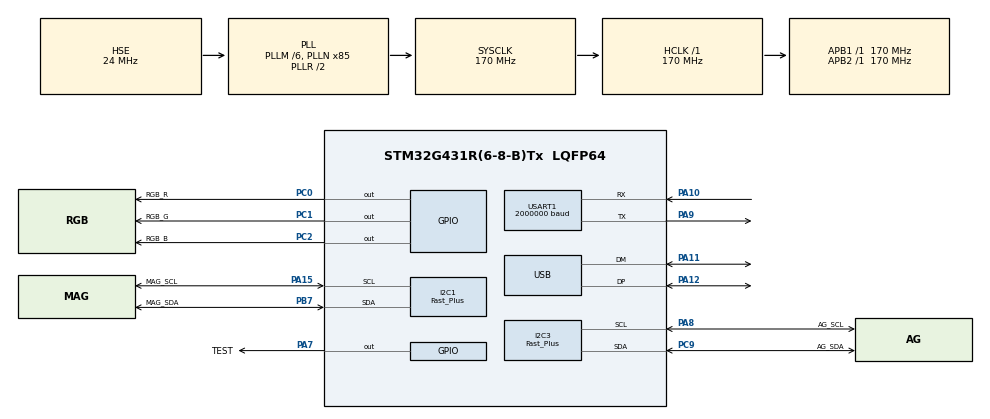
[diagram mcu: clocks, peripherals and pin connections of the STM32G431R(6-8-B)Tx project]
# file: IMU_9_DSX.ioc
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I2C1.CustomTiming=Disabled
I2C1.I2C_Fall_Time=0
I2C1.I2C_Rise_Time=0
I2C1.I2C_Speed_Mode=I2C_Fast_Plus
I2C1.Timing=0x00802172
I2C3.Analog_Filter=I2C_ANALOGFILTER_DISABLE
I2C3.CustomTiming=Disabled
I2C3.I2C_Speed_Mode=I2C_Fast_Plus
I2C3.Timing=0x00802C78
Mcu.Family=STM32G4
Mcu.Name=STM32G431R(6-8-B)Tx
Mcu.Package=LQFP64
NVIC.PriorityGroup=NVIC_PRIORITYGROUP_4
NVIC.TIM2_IRQn=true\:0\:0\:false\:false\:true\:true\:true\:true
NVIC.USART1_IRQn=true\:1\:0\:true\:false\:true\:true\:true\:true
NVIC.USB_LP_IRQn=true\:0\:0\:false\:false\:true\:false\:true\:true
PA10.Mode=Asynchronous
PA10.Signal=USART1_RX
PA11.Mode=Device
PA11.Signal=USB_DM
PA12.Mode=Device
PA12.Signal=USB_DP
PA13.Mode=Serial_Wire
PA13.Signal=SYS_JTMS-SWDIO
PA14.Mode=Serial_Wire
PA14.Signal=SYS_JTCK-SWCLK
PA15.GPIO_Label=MAG_SCL
PA15.Mode=I2C
PA15.Signal=I2C1_SCL
PA7.GPIO_Label=TEST
PA7.Signal=GPIO_Output
PA8.GPIO_Label=AG_SCL
PA8.Mode=I2C
PA8.Signal=I2C3_SCL
PA9.Mode=Asynchronous
PA9.Signal=USART1_TX
PB7.GPIO_Label=MAG_SDA
PB7.Mode=I2C
PB7.Signal=I2C1_SDA
PC0.GPIO_Label=RGB_R
PC0.Signal=GPIO_Output
PC1.GPIO_Label=RGB_G
PC1.Signal=GPIO_Output
PC2.GPIO_Label=RGB_B
PC2.Signal=GPIO_Output
PC9.GPIO_Label=AG_SDA
PC9.Mode=I2C
PC9.Signal=I2C3_SDA
PF0-OSC_IN.Mode=HSE-External-Oscillator
PF0-OSC_IN.Signal=RCC_OSC_IN
PF1-OSC_OUT.Mode=HSE-External-Oscillator
PF1-OSC_OUT.Signal=RCC_OSC_OUT
ProjectManager.HeapSize=0x400
ProjectManager.StackSize=0x800
ProjectManager.TargetToolchain=STM32CubeIDE
RCC.ADC12Freq_Value=170000000
RCC.AHBFreq_Value=170000000
RCC.APB1Freq_Value=170000000
RCC.APB1TimFreq_Value=170000000
RCC.APB2Freq_Value=170000000
RCC.APB2TimFreq_Value=170000000
RCC.CK48CLockSelection=RCC_USBCLKSOURCE_HSI48
RCC.CortexFreq_Value=170000000
RCC.EXTERNAL_CLOCK_VALUE=12288000
RCC.HCLKFreq_Value=170000000
RCC.HSE_VALUE=24000000
RCC.HSI48_VALUE=48000000
RCC.HSI_VALUE=16000000
RCC.LSE_VALUE=32768
RCC.PLLM=RCC_PLLM_DIV6
RCC.PLLN=85
RCC.PLLSourceVirtual=RCC_PLLSOURCE_HSE
RCC.SYSCLKFreq_VALUE=170000000
RCC.SYSCLKSource=RCC_SYSCLKSOURCE_PLLCLK
RCC.USBFreq_Value=48000000
RCC.VCOOutputFreq_Value=340000000
TIM2.AutoReloadPreload=TIM_AUTORELOAD_PRELOAD_ENABLE
TIM2.PeriodNoDither=1000-1
TIM2.Prescaler=170-1
USART1.BaudRate=2000000
USART1.VirtualMode-Asynchronous=VM_ASYNC
USB_DEVICE.CLASS_NAME_FS=CDC
USB_DEVICE.VirtualMode=Cdc
USB_DEVICE.VirtualModeFS=Cdc_FS
VP_SYS_VS_DBSignals.Mode=DisableDeadBatterySignals
VP_TIM2_VS_ClockSourceINT.Mode=Internal
VP_USB_DEVICE_VS_USB_DEVICE_CDC_FS.Mode=CDC_FS
board=custom

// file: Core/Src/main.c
/* USER CODE BEGIN Header */
/**
  ******************************************************************************
  * @file           : main.c
  * @brief          : Main program body
  ******************************************************************************
  * @attention
  *
  * Copyright (c) 2024 STMicroelectronics.
  * All rights reserved.
  *
  * This software is licensed under terms that can be found in the LICENSE file
  * in the root directory of this software component.
  * If no LICENSE file comes with this software, it is provided AS-IS.
  *
  ******************************************************************************
  */
/* USER CODE END Header */
#include "main.h"
#include "i2c.h"
#include "tim.h"
#include "usart.h"
#include "usb_device.h"
#include "gpio.h"

/* USER CODE BEGIN Includes */
#include "acc_gry.h"
#include "magnetic.h"
#include "imu_9.h"
#include "in_flash.h"
#include "user_shell.h"
/* USER CODE END Includes */

void SystemClock_Config(void);

int main(void)
{

  /* MCU Configuration--------------------------------------------------------*/

  /* Reset of all peripherals, Initializes the Flash interface and the Systick. */
  HAL_Init();

  /* Configure the system clock */
  SystemClock_Config();

  /* Initialize all configured peripherals */
  MX_GPIO_Init();
  MX_I2C1_Init();
  MX_I2C3_Init();
  MX_TIM2_Init();
  MX_USART1_UART_Init();
  MX_USB_Device_Init();
  /* USER CODE BEGIN 2 */
  HAL_Delay(1000);
  user_shell_init();
  imu_init();
//  uart_debug_init();
  /* USER CODE END 2 */

  /* Infinite loop */
  while (1)
  {

    /* USER CODE BEGIN 3 */
	  imu_9_shell_cmd_to_do();
  }
  /* USER CODE END 3 */
}

void SystemClock_Config(void)
{
  RCC_OscInitTypeDef RCC_OscInitStruct = {0};
  RCC_ClkInitTypeDef RCC_ClkInitStruct = {0};

  /** Configure the main internal regulator output voltage
  */
  HAL_PWREx_ControlVoltageScaling(PWR_REGULATOR_VOLTAGE_SCALE1_BOOST);

  /** Initializes the RCC Oscillators according to the specified parameters
  * in the RCC_OscInitTypeDef structure.
  */
  RCC_OscInitStruct.OscillatorType = RCC_OSCILLATORTYPE_HSI48|RCC_OSCILLATORTYPE_HSE;
  RCC_OscInitStruct.HSEState = RCC_HSE_ON;
  RCC_OscInitStruct.HSI48State = RCC_HSI48_ON;
  RCC_OscInitStruct.PLL.PLLState = RCC_PLL_ON;
  RCC_OscInitStruct.PLL.PLLSource = RCC_PLLSOURCE_HSE;
  RCC_OscInitStruct.PLL.PLLM = RCC_PLLM_DIV6;
  RCC_OscInitStruct.PLL.PLLN = 85;
  RCC_OscInitStruct.PLL.PLLP = RCC_PLLP_DIV2;
  RCC_OscInitStruct.PLL.PLLQ = RCC_PLLQ_DIV2;
  RCC_OscInitStruct.PLL.PLLR = RCC_PLLR_DIV2;
  if (HAL_RCC_OscConfig(&RCC_OscInitStruct) != HAL_OK)
  {
    Error_Handler();
  }

  /** Initializes the CPU, AHB and APB buses clocks
  */
  RCC_ClkInitStruct.ClockType = RCC_CLOCKTYPE_HCLK|RCC_CLOCKTYPE_SYSCLK
                              |RCC_CLOCKTYPE_PCLK1|RCC_CLOCKTYPE_PCLK2;
  RCC_ClkInitStruct.SYSCLKSource = RCC_SYSCLKSOURCE_PLLCLK;
  RCC_ClkInitStruct.AHBCLKDivider = RCC_SYSCLK_DIV1;
  RCC_ClkInitStruct.APB1CLKDivider = RCC_HCLK_DIV1;
  RCC_ClkInitStruct.APB2CLKDivider = RCC_HCLK_DIV1;

  if (HAL_RCC_ClockConfig(&RCC_ClkInitStruct, FLASH_LATENCY_4) != HAL_OK)
  {
    Error_Handler();
  }
}

void Error_Handler(void)
{
  __disable_irq();
  while (1)
  {
  }
}
